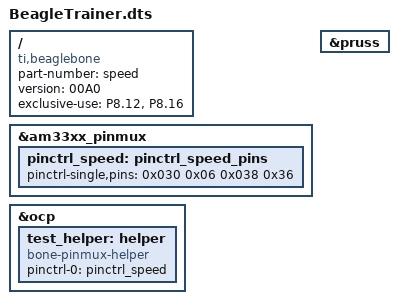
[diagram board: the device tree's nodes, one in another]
/*
 *
 */
/dts-v1/;
/plugin/;

/ {
    compatible = "ti,beaglebone", "ti,beaglebone-black";

    /* identification */
    part-number = "speed";
    version     = "00A0";
    
    exclusive-use =  
        "P8.12",
        "P8.16";  

    fragment@0 {
        target = <&am33xx_pinmux>;
        __overlay__ {
        	pinctrl_speed: pinctrl_speed_pins {
        		pinctrl-single,pins = <
                        0x030 0x06  /* GPIO1_12 - Mode 6 */ 
                        0x038 0x36  /* GPIO1_14 - Mode 6, Pull-Up, RxActive */ 
        		>;
        	};
        };
    };
    
    fragment@1 {
        target = <&ocp>;
        __overlay__ {
            test_helper: helper {  
                compatible = "bone-pinmux-helper"; 
                pinctrl-names = "default";
                pinctrl-0 = <&pinctrl_speed>;
                status = "okay";
            };
        };
    };
    
    fragment@2{  
        target = <&pruss>;  
        __overlay__ {  
            status = "okay";  
        };  
    };  

};
